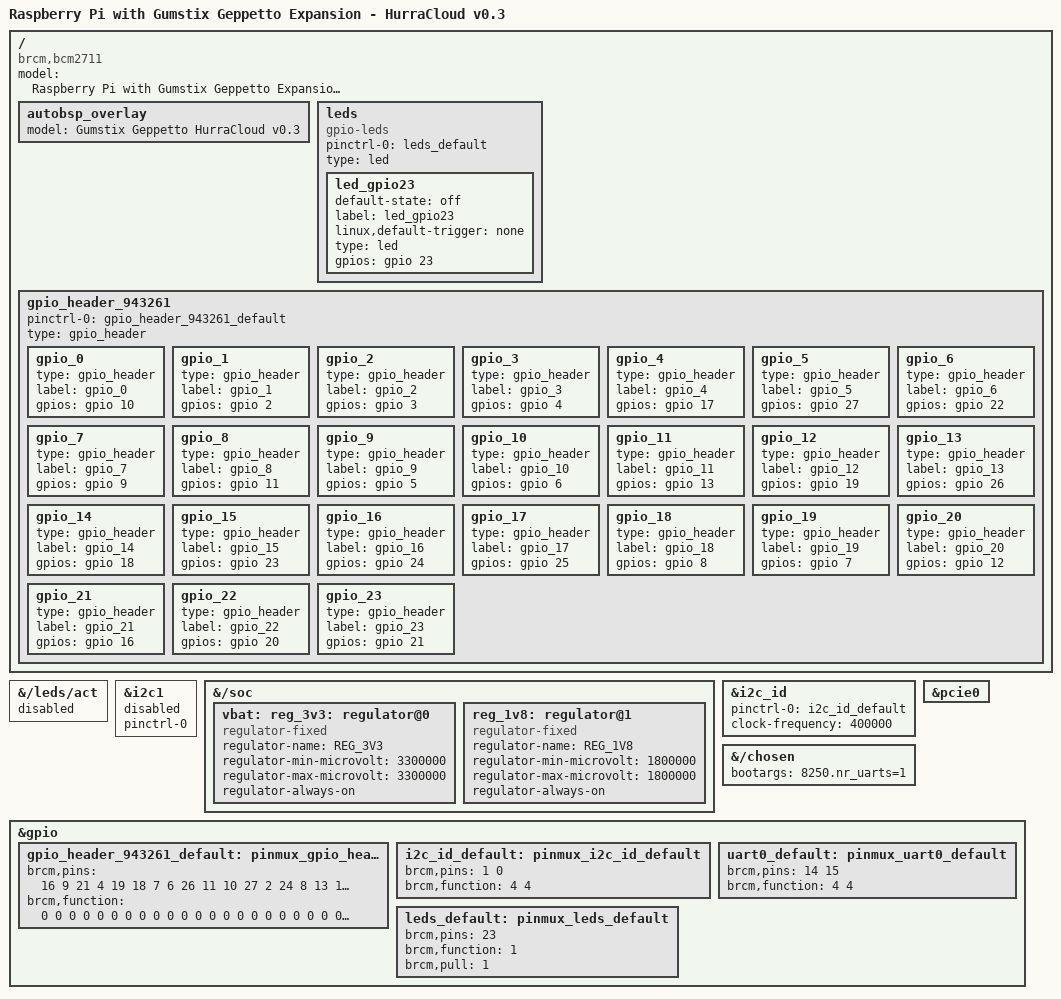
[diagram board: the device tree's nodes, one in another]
/*
* Copyright (C) 2021 Gumstix, Inc. - https://www.gumstix.com/
*
* This program is free software; you can redistribute it and/or modify
* it under the terms of the GNU General Public License version 2 or
* (at your option) any later version as published by the Free Software
* Foundation.
*
* This program is distributed in the hope that it will be useful,
* but WITHOUT ANY WARRANTY; without even the implied warranty of
* MERCHANTABILITY or FITNESS FOR A PARTICULAR PURPOSE.  See the
* GNU General Public License for more details.
*
*/

/dts-v1/;
/plugin/;
#define GPIO_ACTIVE_LOW 1
#define GPIO_ACTIVE_HIGH 0
#define IRQ_TYPE_LEVEL_LOW 8
#define IRQ_TYPE_LEVEL_HIGH 4

/ {
    compatible = "brcm,bcm2711";

    fragment@0 {
        target-path = "/";
        __overlay__ {
            model = "Raspberry Pi with Gumstix Geppetto Expansion - HurraCloud v0.3";
            autobsp_overlay {
                model = "Gumstix Geppetto HurraCloud v0.3";
                status = "okay";
            };

            leds {
                status = "okay";
                pinctrl-names = "default";
                pinctrl-0 = <&leds_default>;
                compatible = "gpio-leds";
                type = "led";
                
                    led_gpio23 {
                    status = "okay";
                    default-state = "off";
                    label = "led_gpio23";
                    linux,default-trigger = "none";
                    type = "led";
                    gpios = <&gpio 23 GPIO_ACTIVE_HIGH>;


                };
            };
            gpio_header_943261 {
                status = "okay";
                pinctrl-names = "default";
                pinctrl-0 = <&gpio_header_943261_default>;
                type = "gpio_header";
                
                    gpio_0 {
                    status = "okay";
                    type = "gpio_header";
                    label = "gpio_0";
                    gpios = <&gpio 10 0>;


                };
                
                    gpio_1 {
                    status = "okay";
                    type = "gpio_header";
                    label = "gpio_1";
                    gpios = <&gpio 2 0>;


                };
                
                    gpio_2 {
                    status = "okay";
                    type = "gpio_header";
                    label = "gpio_2";
                    gpios = <&gpio 3 0>;


                };
                
                    gpio_3 {
                    status = "okay";
                    type = "gpio_header";
                    label = "gpio_3";
                    gpios = <&gpio 4 0>;


                };
                
                    gpio_4 {
                    status = "okay";
                    type = "gpio_header";
                    label = "gpio_4";
                    gpios = <&gpio 17 0>;


                };
                
                    gpio_5 {
                    status = "okay";
                    type = "gpio_header";
                    label = "gpio_5";
                    gpios = <&gpio 27 0>;


                };
                
                    gpio_6 {
                    status = "okay";
                    type = "gpio_header";
                    label = "gpio_6";
                    gpios = <&gpio 22 0>;


                };
                
                    gpio_7 {
                    status = "okay";
                    type = "gpio_header";
                    label = "gpio_7";
                    gpios = <&gpio 9 0>;


                };
                
                    gpio_8 {
                    status = "okay";
                    type = "gpio_header";
                    label = "gpio_8";
                    gpios = <&gpio 11 0>;


                };
                
                    gpio_9 {
                    status = "okay";
                    type = "gpio_header";
                    label = "gpio_9";
                    gpios = <&gpio 5 0>;


                };
                
                    gpio_10 {
                    status = "okay";
                    type = "gpio_header";
                    label = "gpio_10";
                    gpios = <&gpio 6 0>;


                };
                
                    gpio_11 {
                    status = "okay";
                    type = "gpio_header";
                    label = "gpio_11";
                    gpios = <&gpio 13 0>;


                };
                
                    gpio_12 {
                    status = "okay";
                    type = "gpio_header";
                    label = "gpio_12";
                    gpios = <&gpio 19 0>;


                };
                
                    gpio_13 {
                    status = "okay";
                    type = "gpio_header";
                    label = "gpio_13";
                    gpios = <&gpio 26 0>;


                };
                
                    gpio_14 {
                    status = "okay";
                    type = "gpio_header";
                    label = "gpio_14";
                    gpios = <&gpio 18 0>;


                };
                
                    gpio_15 {
                    status = "okay";
                    type = "gpio_header";
                    label = "gpio_15";
                    gpios = <&gpio 23 0>;


                };
                
                    gpio_16 {
                    status = "okay";
                    type = "gpio_header";
                    label = "gpio_16";
                    gpios = <&gpio 24 0>;


                };
                
                    gpio_17 {
                    status = "okay";
                    type = "gpio_header";
                    label = "gpio_17";
                    gpios = <&gpio 25 0>;


                };
                
                    gpio_18 {
                    status = "okay";
                    type = "gpio_header";
                    label = "gpio_18";
                    gpios = <&gpio 8 0>;


                };
                
                    gpio_19 {
                    status = "okay";
                    type = "gpio_header";
                    label = "gpio_19";
                    gpios = <&gpio 7 0>;


                };
                
                    gpio_20 {
                    status = "okay";
                    type = "gpio_header";
                    label = "gpio_20";
                    gpios = <&gpio 12 0>;


                };
                
                    gpio_21 {
                    status = "okay";
                    type = "gpio_header";
                    label = "gpio_21";
                    gpios = <&gpio 16 0>;


                };
                
                    gpio_22 {
                    status = "okay";
                    type = "gpio_header";
                    label = "gpio_22";
                    gpios = <&gpio 20 0>;


                };
                
                    gpio_23 {
                    status = "okay";
                    type = "gpio_header";
                    label = "gpio_23";
                    gpios = <&gpio 21 0>;


                };
            };

        };
    };


    fragment@1 {
        target-path = "/leds/act";
        __overlay__ {
            status = "disabled";
        };
    };

    fragment@2 {
        target = <&i2c1>;
        __overlay__ {
            status = "disabled";
            pinctrl-0;
        };
    };

    fragment@3 {
        target-path = "/soc";
        __overlay__ {
            vbat: reg_3v3: regulator@0 {
                compatible = "regulator-fixed";
                regulator-name = "REG_3V3";
                regulator-min-microvolt = <3300000>;
                regulator-max-microvolt = <3300000>;
                regulator-always-on;
            };

            reg_1v8: regulator@1 {
                compatible = "regulator-fixed";
                regulator-name = "REG_1V8";
                regulator-min-microvolt = <1800000>;
                regulator-max-microvolt = <1800000>;
                regulator-always-on;
            };
        };
    };

// uart0 devices
// i2c_buses devices
    fragment@4 {
        target = <&i2c_id>;
        __overlay__ {
            status = "okay";

            pinctrl-names = "default";
            pinctrl-0 = <&i2c_id_default>;

            clock-frequency = <400000>;
        };
    };
// pcie devices
    fragment@5 {
        target = <&pcie0>;
        __overlay__ {
            status = "okay";


        };
    };

    fragment@6 {
        target-path = "/chosen";
        __overlay__ {
            bootargs = "8250.nr_uarts=1";
        };
    };

    fragment@7 {
        target = <&gpio>;
        __overlay__ {
            gpio_header_943261_default: pinmux_gpio_header_943261_default {
                brcm,pins = <
                    16 /* gpio16.gpio16 */
                    9 /* gpio9.gpio9 */
                    21 /* gpio21.gpio21 */
                    4 /* gpio4.gpio4 */
                    19 /* gpio19.gpio19 */
                    18 /* gpio18.gpio18 */
                    7 /* gpio7.gpio7 */
                    6 /* gpio6.gpio6 */
                    26 /* gpio26.gpio26 */
                    11 /* gpio11.gpio11 */
                    10 /* gpio10.gpio10 */
                    27 /* gpio27.gpio27 */
                    2 /* gpio2.gpio2 */
                    24 /* gpio24.gpio24 */
                    8 /* gpio8.gpio8 */
                    13 /* gpio13.gpio13 */
                    17 /* gpio17.gpio17 */
                    20 /* gpio20.gpio20 */
                    3 /* gpio3.gpio3 */
                    22 /* gpio22.gpio22 */
                    5 /* gpio5.gpio5 */
                    25 /* gpio25.gpio25 */
                    23 /* gpio23.gpio23 */
                    12 /* gpio12.gpio12 */
                >;
            brcm,function = <  0   0   0   0   0   0   0   0   0   0   0   0   0   0   0   0   0   0   0   0   0   0   0   0  >;
            };

            i2c_id_default: pinmux_i2c_id_default {
                brcm,pins = <
                    1 /* gpio1.scl0 */
                    0 /* gpio0.sda0 */
                >;
            brcm,function = <  4   4  >;
            };

            uart0_default: pinmux_uart0_default {
                brcm,pins = <
                    14 /* gpio14.txd0 */
                    15 /* gpio15.rxd0 */
                >;
            brcm,function = <  4   4  >;
            };

            leds_default: pinmux_leds_default {
                brcm,pins = <
                    23 /* gpio23.gpio23 */
                >;
            brcm,function = <  1  >;
            brcm,pull = < 1 >;

            };

        };
    };

};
